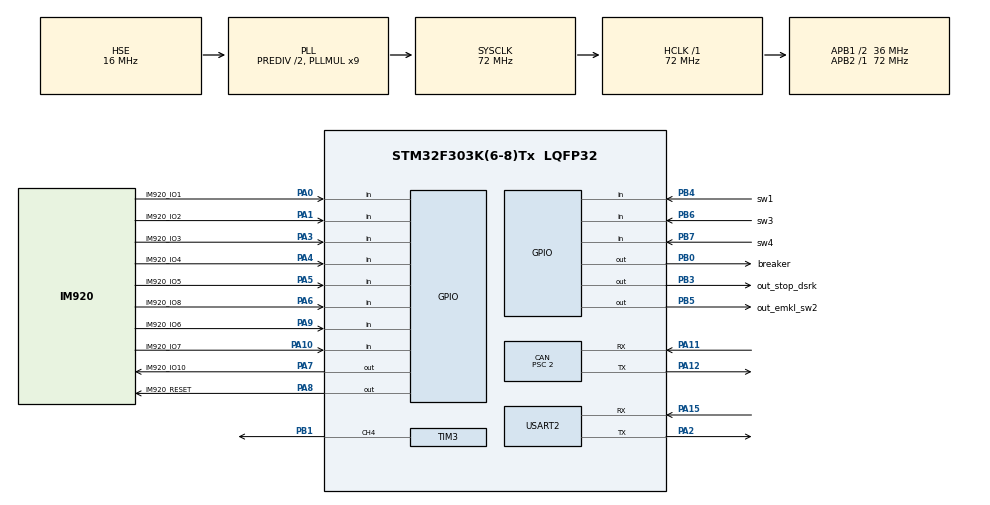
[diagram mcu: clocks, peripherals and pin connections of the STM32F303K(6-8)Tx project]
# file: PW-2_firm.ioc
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CAN.BS1=CAN_BS1_14TQ
CAN.BS2=CAN_BS2_3TQ
CAN.CalculateBaudRate=1000000
CAN.CalculateTimeBit=1000
CAN.CalculateTimeQuantum=55.55555555555556
CAN.Prescaler=2
CAN.SJW=CAN_SJW_1TQ
Dma.Request0=TIM3_CH4/UP
Dma.TIM3_CH4/UP.0.Direction=DMA_MEMORY_TO_PERIPH
Dma.TIM3_CH4/UP.0.Instance=DMA1_Channel3
Dma.TIM3_CH4/UP.0.MemDataAlignment=DMA_MDATAALIGN_BYTE
Dma.TIM3_CH4/UP.0.MemInc=DMA_MINC_ENABLE
Dma.TIM3_CH4/UP.0.Mode=DMA_NORMAL
Dma.TIM3_CH4/UP.0.PeriphDataAlignment=DMA_PDATAALIGN_HALFWORD
Dma.TIM3_CH4/UP.0.PeriphInc=DMA_PINC_DISABLE
Dma.TIM3_CH4/UP.0.Priority=DMA_PRIORITY_VERY_HIGH
Mcu.Family=STM32F3
Mcu.Name=STM32F303K(6-8)Tx
Mcu.Package=LQFP32
NVIC.DMA1_Channel3_IRQn=true\:0\:0\:false\:false\:true\:false\:true\:true
NVIC.PriorityGroup=NVIC_PRIORITYGROUP_4
PA0.GPIO_Label=IM920_IO1
PA0.Signal=GPIO_Input
PA1.GPIO_Label=IM920_IO2
PA1.Signal=GPIO_Input
PA10.GPIO_Label=IM920_IO7
PA10.Signal=GPIO_Input
PA11.Mode=CAN_Activate
PA11.Signal=CAN_RX
PA12.Mode=CAN_Activate
PA12.Signal=CAN_TX
PA13.Mode=Serial_Wire
PA13.Signal=SYS_JTMS-SWDIO
PA14.Mode=Serial_Wire
PA14.Signal=SYS_JTCK-SWCLK
PA15.Mode=Asynchronous
PA15.Signal=USART2_RX
PA2.Mode=Asynchronous
PA2.Signal=USART2_TX
PA3.GPIO_Label=IM920_IO3
PA3.Signal=GPIO_Input
PA4.GPIO_Label=IM920_IO4
PA4.Signal=GPIO_Input
PA5.GPIO_Label=IM920_IO5
PA5.Signal=GPIO_Input
PA6.GPIO_Label=IM920_IO8
PA6.Signal=GPIO_Input
PA7.GPIO_Label=IM920_IO10
PA7.PinState=GPIO_PIN_SET
PA7.Signal=GPIO_Output
PA8.GPIO_Label=IM920_RESET
PA8.Signal=GPIO_Output
PA9.GPIO_Label=IM920_IO6
PA9.Signal=GPIO_Input
PB0.GPIO_Label=breaker
PB0.Signal=GPIO_Output
PB1.Signal=S_TIM3_CH4
PB3.GPIO_Label=out_stop_dsrk
PB3.Signal=GPIO_Output
PB4.GPIO_Label=sw1
PB4.GPIO_PuPd=GPIO_PULLUP
PB4.Signal=GPIO_Input
PB5.GPIO_Label=out_emkl_sw2
PB5.Signal=GPIO_Output
PB6.GPIO_Label=sw3
PB6.GPIO_PuPd=GPIO_PULLUP
PB6.Signal=GPIO_Input
PB7.GPIO_Label=sw4
PB7.GPIO_PuPd=GPIO_PULLUP
PB7.Signal=GPIO_Input
PF0\ /\ OSC_IN.Mode=HSE-External-Oscillator
PF0\ /\ OSC_IN.Signal=RCC_OSC_IN
PF1\ /\ OSC_OUT.Mode=HSE-External-Oscillator
PF1\ /\ OSC_OUT.Signal=RCC_OSC_OUT
ProjectManager.HeapSize=0x200
ProjectManager.StackSize=0x400
ProjectManager.TargetToolchain=STM32CubeIDE
RCC.AHBFreq_Value=72000000
RCC.APB1CLKDivider=RCC_HCLK_DIV2
RCC.APB1Freq_Value=36000000
RCC.APB1TimFreq_Value=72000000
RCC.APB2Freq_Value=72000000
RCC.APB2TimFreq_Value=72000000
RCC.CortexFreq_Value=72000000
RCC.HCLKFreq_Value=72000000
RCC.HSE_VALUE=16000000
RCC.HSI_VALUE=8000000
RCC.PLLMUL=RCC_PLL_MUL9
RCC.PLLSourceVirtual=RCC_PLLSOURCE_HSE
RCC.RCC_PLLsource_Clock_Source_FROM_HSE=RCC_HSE_PREDIV_DIV2
RCC.SYSCLKFreq_VALUE=72000000
RCC.SYSCLKSourceVirtual=RCC_SYSCLKSOURCE_PLLCLK
SH.S_TIM3_CH4.0=TIM3_CH4,PWM Generation4 CH4
TIM3.Channel-PWM\ Generation4\ CH4=TIM_CHANNEL_4
TIM3.Period=89
USART2.VirtualMode-Asynchronous=VM_ASYNC
board=custom

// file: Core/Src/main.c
/* USER CODE BEGIN Header */
/**
  ******************************************************************************
  * @file           : main.c
  * @brief          : Main program body
  ******************************************************************************
  * @attention
  *
  * Copyright (c) 2022 STMicroelectronics.
  * All rights reserved.
  *
  * This software is licensed under terms that can be found in the LICENSE file
  * in the root directory of this software component.
  * If no LICENSE file comes with this software, it is provided AS-IS.
  *
  ******************************************************************************
  */
/* USER CODE END Header */
#include "main.h"

/* USER CODE BEGIN Includes */
#include "CAN303x8.h"
#include "NeoPixel.h"
/* USER CODE END Includes */

CAN_HandleTypeDef hcan;

TIM_HandleTypeDef htim3;
DMA_HandleTypeDef hdma_tim3_ch4_up;

UART_HandleTypeDef huart2;

void SystemClock_Config(void);
static void MX_GPIO_Init(void);
static void MX_DMA_Init(void);
static void MX_CAN_Init(void);
static void MX_TIM3_Init(void);
static void MX_USART2_UART_Init(void);

int main(void)
{

  /* MCU Configuration--------------------------------------------------------*/

  /* Reset of all peripherals, Initializes the Flash interface and the Systick. */
  HAL_Init();

  /* Configure the system clock */
  SystemClock_Config();

  /* Initialize all configured peripherals */
  MX_GPIO_Init();
  MX_DMA_Init();
  MX_CAN_Init();
  MX_TIM3_Init();
  MX_USART2_UART_Init();
  /* USER CODE BEGIN 2 */
  stm_CAN::CAN_303x8 can(&hcan);
  ws2812::NeoPixel pixels(&htim3, &hdma_tim3_ch4_up, 45, 22);

  const ws2812::color _orenge = {48, 24, 0};
  const ws2812::color _blue = {0, 48, 128};
  const ws2812::color _green = {0, 48, 0};
  const ws2812::color _purple = {24, 0, 72};
  const ws2812::color _white = {12, 16, 32};
  const ws2812::color _full = {255, 255, 255};

  /* USER CODE END 2 */

  /* Infinite loop */
  /* USER CODE BEGIN WHILE */
  while (1)
  {
    uint8_t switches =
      HAL_GPIO_ReadPin(sw1_GPIO_Port, sw1_Pin) |
      (HAL_GPIO_ReadPin(sw2_GPIO_Port, sw2_Pin) << 1) |
      (HAL_GPIO_ReadPin(sw3_GPIO_Port, sw3_Pin) << 2) |
      (HAL_GPIO_ReadPin(sw4_GPIO_Port, sw4_Pin) << 3);

    HAL_GPIO_WritePin(breaker_GPIO_Port, breaker_Pin, switches && 0x00);

    if(switches && 0x00){
      for(int i = 0; i < 45; i++){
        pixels.colors[i] = _blue;
      }
    }else{
      for(int i = 0; i < 4; i++){
        if(switches & (1 << i)){
          pixels.colors[i] = _white;
        }else{
          pixels.colors[i] = _orenge;
        }
      }
    }
    pixels.rend();

    HAL_Delay(1);
    /* USER CODE END WHILE */

  }
}

void SystemClock_Config(void)
{
  RCC_OscInitTypeDef RCC_OscInitStruct = {0};
  RCC_ClkInitTypeDef RCC_ClkInitStruct = {0};

  /** Initializes the RCC Oscillators according to the specified parameters
  * in the RCC_OscInitTypeDef structure.
  */
  RCC_OscInitStruct.OscillatorType = RCC_OSCILLATORTYPE_HSE;
  RCC_OscInitStruct.HSEState = RCC_HSE_ON;
  RCC_OscInitStruct.HSEPredivValue = RCC_HSE_PREDIV_DIV2;
  RCC_OscInitStruct.HSIState = RCC_HSI_ON;
  RCC_OscInitStruct.PLL.PLLState = RCC_PLL_ON;
  RCC_OscInitStruct.PLL.PLLSource = RCC_PLLSOURCE_HSE;
  RCC_OscInitStruct.PLL.PLLMUL = RCC_PLL_MUL9;
  if (HAL_RCC_OscConfig(&RCC_OscInitStruct) != HAL_OK)
  {
    Error_Handler();
  }

  /** Initializes the CPU, AHB and APB buses clocks
  */
  RCC_ClkInitStruct.ClockType = RCC_CLOCKTYPE_HCLK|RCC_CLOCKTYPE_SYSCLK
                              |RCC_CLOCKTYPE_PCLK1|RCC_CLOCKTYPE_PCLK2;
  RCC_ClkInitStruct.SYSCLKSource = RCC_SYSCLKSOURCE_PLLCLK;
  RCC_ClkInitStruct.AHBCLKDivider = RCC_SYSCLK_DIV1;
  RCC_ClkInitStruct.APB1CLKDivider = RCC_HCLK_DIV2;
  RCC_ClkInitStruct.APB2CLKDivider = RCC_HCLK_DIV1;

  if (HAL_RCC_ClockConfig(&RCC_ClkInitStruct, FLASH_LATENCY_2) != HAL_OK)
  {
    Error_Handler();
  }
}

static void MX_CAN_Init(void)
{

  hcan.Instance = CAN;
  hcan.Init.Prescaler = 2;
  hcan.Init.Mode = CAN_MODE_NORMAL;
  hcan.Init.SyncJumpWidth = CAN_SJW_1TQ;
  hcan.Init.TimeSeg1 = CAN_BS1_14TQ;
  hcan.Init.TimeSeg2 = CAN_BS2_3TQ;
  hcan.Init.TimeTriggeredMode = DISABLE;
  hcan.Init.AutoBusOff = DISABLE;
  hcan.Init.AutoWakeUp = DISABLE;
  hcan.Init.AutoRetransmission = DISABLE;
  hcan.Init.ReceiveFifoLocked = DISABLE;
  hcan.Init.TransmitFifoPriority = DISABLE;
  if (HAL_CAN_Init(&hcan) != HAL_OK)
  {
    Error_Handler();
  }

}

static void MX_TIM3_Init(void)
{

  TIM_MasterConfigTypeDef sMasterConfig = {0};
  TIM_OC_InitTypeDef sConfigOC = {0};

  htim3.Instance = TIM3;
  htim3.Init.Prescaler = 0;
  htim3.Init.CounterMode = TIM_COUNTERMODE_UP;
  htim3.Init.Period = 89;
  htim3.Init.ClockDivision = TIM_CLOCKDIVISION_DIV1;
  htim3.Init.AutoReloadPreload = TIM_AUTORELOAD_PRELOAD_DISABLE;
  if (HAL_TIM_PWM_Init(&htim3) != HAL_OK)
  {
    Error_Handler();
  }
  sMasterConfig.MasterOutputTrigger = TIM_TRGO_RESET;
  sMasterConfig.MasterSlaveMode = TIM_MASTERSLAVEMODE_DISABLE;
  if (HAL_TIMEx_MasterConfigSynchronization(&htim3, &sMasterConfig) != HAL_OK)
  {
    Error_Handler();
  }
  sConfigOC.OCMode = TIM_OCMODE_PWM1;
  sConfigOC.Pulse = 0;
  sConfigOC.OCPolarity = TIM_OCPOLARITY_HIGH;
  sConfigOC.OCFastMode = TIM_OCFAST_DISABLE;
  if (HAL_TIM_PWM_ConfigChannel(&htim3, &sConfigOC, TIM_CHANNEL_4) != HAL_OK)
  {
    Error_Handler();
  }
  HAL_TIM_MspPostInit(&htim3);

}

static void MX_USART2_UART_Init(void)
{

  huart2.Instance = USART2;
  huart2.Init.BaudRate = 38400;
  huart2.Init.WordLength = UART_WORDLENGTH_8B;
  huart2.Init.StopBits = UART_STOPBITS_1;
  huart2.Init.Parity = UART_PARITY_NONE;
  huart2.Init.Mode = UART_MODE_TX_RX;
  huart2.Init.HwFlowCtl = UART_HWCONTROL_NONE;
  huart2.Init.OverSampling = UART_OVERSAMPLING_16;
  huart2.Init.OneBitSampling = UART_ONE_BIT_SAMPLE_DISABLE;
  huart2.AdvancedInit.AdvFeatureInit = UART_ADVFEATURE_NO_INIT;
  if (HAL_UART_Init(&huart2) != HAL_OK)
  {
    Error_Handler();
  }

}

static void MX_DMA_Init(void)
{

  /* DMA controller clock enable */
  __HAL_RCC_DMA1_CLK_ENABLE();

  /* DMA interrupt init */
  /* DMA1_Channel3_IRQn interrupt configuration */
  HAL_NVIC_SetPriority(DMA1_Channel3_IRQn, 0, 0);
  HAL_NVIC_EnableIRQ(DMA1_Channel3_IRQn);

}

static void MX_GPIO_Init(void)
{
  GPIO_InitTypeDef GPIO_InitStruct = {0};

  /* GPIO Ports Clock Enable */
  __HAL_RCC_GPIOF_CLK_ENABLE();
  __HAL_RCC_GPIOA_CLK_ENABLE();
  __HAL_RCC_GPIOB_CLK_ENABLE();

  /*Configure GPIO pin Output Level */
  HAL_GPIO_WritePin(breaker_GPIO_Port, breaker_Pin, GPIO_PIN_RESET);

  /*Configure GPIO pin : breaker_Pin */
  GPIO_InitStruct.Pin = breaker_Pin;
  GPIO_InitStruct.Mode = GPIO_MODE_OUTPUT_PP;
  GPIO_InitStruct.Pull = GPIO_NOPULL;
  GPIO_InitStruct.Speed = GPIO_SPEED_FREQ_LOW;
  HAL_GPIO_Init(breaker_GPIO_Port, &GPIO_InitStruct);

  /*Configure GPIO pins : sw1_Pin sw2_Pin sw3_Pin sw4_Pin */
  GPIO_InitStruct.Pin = sw1_Pin|sw2_Pin|sw3_Pin|sw4_Pin;
  GPIO_InitStruct.Mode = GPIO_MODE_INPUT;
  GPIO_InitStruct.Pull = GPIO_PULLUP;
  HAL_GPIO_Init(GPIOB, &GPIO_InitStruct);

}

void Error_Handler(void)
{
  __disable_irq();
  while (1)
  {
  }
}
